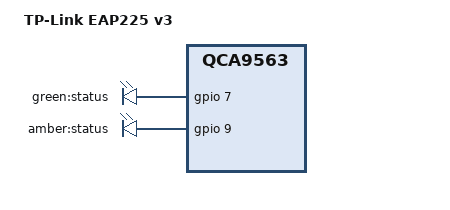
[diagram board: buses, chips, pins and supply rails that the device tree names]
// SPDX-License-Identifier: GPL-2.0-or-later OR MIT

#include "qca9563_tplink_eap2x5-1port.dtsi"

/ {
	compatible = "tplink,eap225-v3", "qca,qca9563";
	model = "TP-Link EAP225 v3";

	aliases {
		led-boot = &led_status_green;
		led-failsafe = &led_status_amber;
		led-running = &led_status_green;
		led-upgrade = &led_status_amber;
	};

	leds {
		compatible = "gpio-leds";

		led_status_green: status_green {
			label = "green:status";
			gpios = <&gpio 7 GPIO_ACTIVE_HIGH>;
			default-state = "on";
		};

		led_status_amber: status_amber {
			label = "amber:status";
			gpios = <&gpio 9 GPIO_ACTIVE_HIGH>;
		};
	};
};
